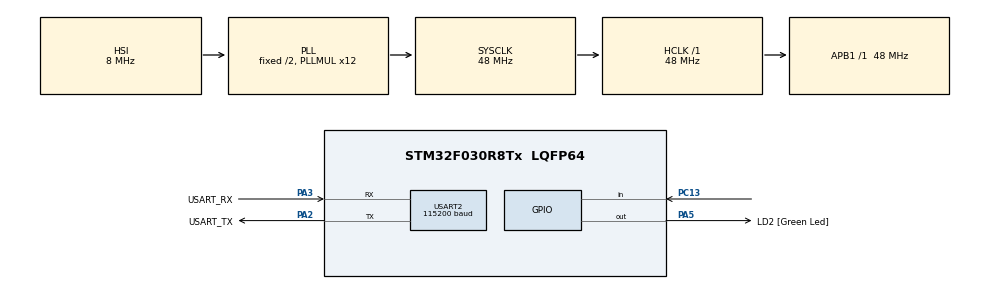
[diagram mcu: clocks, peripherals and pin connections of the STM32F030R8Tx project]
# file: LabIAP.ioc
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CRC.DefaultInitValueUse=DEFAULT_INIT_VALUE_ENABLE
Mcu.Family=STM32F0
Mcu.Name=STM32F030R8Tx
Mcu.Package=LQFP64
PA13.GPIO_Label=TMS
PA13.Mode=Serial-WireDebug
PA13.Signal=SYS_SWDIO
PA14.GPIO_Label=TCK
PA14.Mode=Serial-WireDebug
PA14.Signal=SYS_SWCLK
PA2.GPIO_Label=USART_TX
PA2.GPIO_Mode=GPIO_MODE_AF_PP
PA2.GPIO_PuPd=GPIO_NOPULL
PA2.GPIO_Speed=GPIO_SPEED_HIGH
PA2.Mode=Asynchronous
PA2.Signal=USART2_TX
PA3.GPIO_Label=USART_RX
PA3.GPIO_Mode=GPIO_MODE_AF_PP
PA3.GPIO_PuPd=GPIO_NOPULL
PA3.GPIO_Speed=GPIO_SPEED_HIGH
PA3.Mode=Asynchronous
PA3.Signal=USART2_RX
PA5.GPIO_Label=LD2 [Green Led]
PA5.GPIO_Mode=GPIO_MODE_OUTPUT_PP
PA5.GPIO_ModeDefaultOutputPP=GPIO_MODE_OUTPUT_PP
PA5.GPIO_PuPd=GPIO_NOPULL
PA5.GPIO_Speed=GPIO_SPEED_HIGH
PA5.Signal=GPIO_Output
PC13.Signal=GPIO_Input
PC14-OSC32_IN.Signal=RCC_OSC32_IN
PC15-OSC32_OUT.Signal=RCC_OSC32_OUT
PF0-OSC_IN.Signal=RCC_OSC_IN
PF1-OSC_OUT.Signal=RCC_OSC_OUT
ProjectManager.TargetToolchain=EWARM
RCC.AHBFreq_Value=48000000
RCC.APB1Freq_Value=48000000
RCC.APB1TimFreq_Value=48000000
RCC.HCLKFreq_Value=48000000
RCC.PLLMUL=RCC_PLL_MUL12
RCC.SYSCLKFreq_VALUE=48000000
RCC.SYSCLKSource=RCC_SYSCLKSOURCE_PLLCLK
USART2.BaudRate=115200
VP_CRC_VS_CRC.Mode=CRC_Activate
board=custom

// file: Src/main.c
/**
  ******************************************************************************
  * File Name          : main.c
  * Description        : Main program body
  ******************************************************************************
  *
  * COPYRIGHT(c) 2015 STMicroelectronics
  *
  * Redistribution and use in source and binary forms, with or without modification,
  * are permitted provided that the following conditions are met:
  *   1. Redistributions of source code must retain the above copyright notice,
  *      this list of conditions and the following disclaimer.
  *   2. Redistributions in binary form must reproduce the above copyright notice,
  *      this list of conditions and the following disclaimer in the documentation
  *      and/or other materials provided with the distribution.
  *   3. Neither the name of STMicroelectronics nor the names of its contributors
  *      may be used to endorse or promote products derived from this software
  *      without specific prior written permission.
  *
  * THIS SOFTWARE IS PROVIDED BY THE COPYRIGHT HOLDERS AND CONTRIBUTORS "AS IS"
  * AND ANY EXPRESS OR IMPLIED WARRANTIES, INCLUDING, BUT NOT LIMITED TO, THE
  * IMPLIED WARRANTIES OF MERCHANTABILITY AND FITNESS FOR A PARTICULAR PURPOSE ARE
  * DISCLAIMED. IN NO EVENT SHALL THE COPYRIGHT HOLDER OR CONTRIBUTORS BE LIABLE
  * FOR ANY DIRECT, INDIRECT, INCIDENTAL, SPECIAL, EXEMPLARY, OR CONSEQUENTIAL
  * DAMAGES (INCLUDING, BUT NOT LIMITED TO, PROCUREMENT OF SUBSTITUTE GOODS OR
  * SERVICES; LOSS OF USE, DATA, OR PROFITS; OR BUSINESS INTERRUPTION) HOWEVER
  * CAUSED AND ON ANY THEORY OF LIABILITY, WHETHER IN CONTRACT, STRICT LIABILITY,
  * OR TORT (INCLUDING NEGLIGENCE OR OTHERWISE) ARISING IN ANY WAY OUT OF THE USE
  * OF THIS SOFTWARE, EVEN IF ADVISED OF THE POSSIBILITY OF SUCH DAMAGE.
  *
  ******************************************************************************
  */
#include "stm32f0xx_hal.h"
#include "crc.h"
#include "usart.h"
#include "gpio.h"

/* USER CODE BEGIN Includes */
#include "main.h"
#include "menu.h"
/* USER CODE END Includes */

/* USER CODE BEGIN PV */
/* Private variables ---------------------------------------------------------*/
extern pFunction JumpToApplication;
extern uint32_t JumpAddress;
/* USER CODE END PV */

void SystemClock_Config(void);

/* USER CODE BEGIN PFP */
/* Private function prototypes -----------------------------------------------*/

/* USER CODE END PFP */

int main(void)
{

  /* MCU Configuration----------------------------------------------------------*/

  /* Reset of all peripherals, Initializes the Flash interface and the Systick. */
  HAL_Init();

  /* Configure the system clock */
  SystemClock_Config();

  /* Initialize all configured peripherals */
  MX_GPIO_Init();
  MX_CRC_Init();
  MX_USART2_UART_Init();

  /* USER CODE BEGIN 2 */
 /* Test if Key push-button is pressed */
  if (HAL_GPIO_ReadPin(GPIOC, GPIO_PIN_13) == GPIO_PIN_RESET)
  {
    /* Initialise Flash */
    FLASH_If_Init();
    /* Display main menu */
    Main_Menu ();
  }
  /* Keep the user application running */
  else
  {
    /* Test if user code is programmed starting from address "APPLICATION_ADDRESS" */
    if (((*(__IO uint32_t*)APPLICATION_ADDRESS) & 0x2FFE0000 ) == 0x20000000)
    {
      /* Jump to user application */
      JumpAddress = *(__IO uint32_t*) (APPLICATION_ADDRESS + 4);
      JumpToApplication = (pFunction) JumpAddress;
      /* Initialize user application's Stack Pointer */
      __set_MSP(*(__IO uint32_t*) APPLICATION_ADDRESS);
      JumpToApplication();
    }
  }

  /* USER CODE END 2 */

  /* Infinite loop */
  while (1)
  {

  }

}

/** System Clock Configuration
*/
void SystemClock_Config(void)
{

  RCC_OscInitTypeDef RCC_OscInitStruct;
  RCC_ClkInitTypeDef RCC_ClkInitStruct;

  RCC_OscInitStruct.OscillatorType = RCC_OSCILLATORTYPE_HSI;
  RCC_OscInitStruct.HSIState = RCC_HSI_ON;
  RCC_OscInitStruct.HSICalibrationValue = 16;
  RCC_OscInitStruct.PLL.PLLState = RCC_PLL_ON;
  RCC_OscInitStruct.PLL.PLLSource = RCC_PLLSOURCE_HSI;
  RCC_OscInitStruct.PLL.PLLMUL = RCC_PLL_MUL12;
  RCC_OscInitStruct.PLL.PREDIV = RCC_PREDIV_DIV1;
  HAL_RCC_OscConfig(&RCC_OscInitStruct);

  RCC_ClkInitStruct.ClockType = RCC_CLOCKTYPE_SYSCLK;
  RCC_ClkInitStruct.SYSCLKSource = RCC_SYSCLKSOURCE_PLLCLK;
  RCC_ClkInitStruct.AHBCLKDivider = RCC_SYSCLK_DIV1;
  RCC_ClkInitStruct.APB1CLKDivider = RCC_HCLK_DIV1;
  HAL_RCC_ClockConfig(&RCC_ClkInitStruct, FLASH_LATENCY_1);

  HAL_SYSTICK_Config(HAL_RCC_GetHCLKFreq()/1000);

  HAL_SYSTICK_CLKSourceConfig(SYSTICK_CLKSOURCE_HCLK);

}

/************************ (C) COPYRIGHT STMicroelectronics *****END OF FILE****/
